# STM32WB55_CM0P register map
File version: 2.1
CPU: CM0 r0p1, little endian, MPU, no FPU, 4 interrupt priority bits
Registers are 32-bit, read-write, reset 0x0 unless marked. A register's access mark holds for its fields unless they carry their own. Offsets are from the block's base; [hi:lo] are bit positions; {n}, {i} and the like mark numbered series.

## GPIOH — General-purpose I/Os
Base 0x48001C00
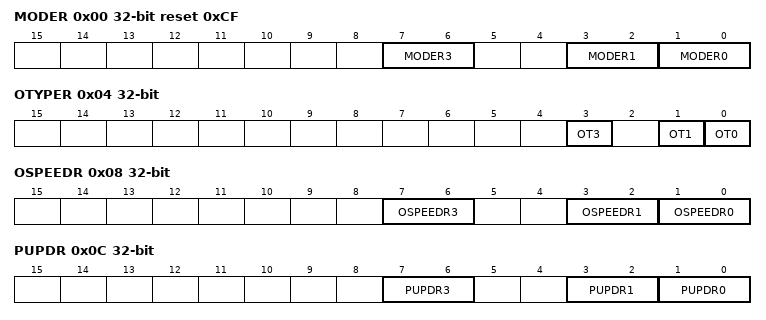
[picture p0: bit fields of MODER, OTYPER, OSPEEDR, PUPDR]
0x00 MODER reset 0xCF — GPIO port mode register
  [7:6] MODER3 — Port x configuration bits (y = 0..15)
  [3:2] MODER1 — Port x configuration bits (y = 0..15)
  [1:0] MODER0 — Port x configuration bits (y = 0..15)
0x04 OTYPER — GPIO port output type register
  [3] OT3 — Port x configuration bits (y = 0..15)
  [1] OT1 — Port x configuration bits (y = 0..15)
  [0] OT0 — Port x configuration bits (y = 0..15)
0x08 OSPEEDR — GPIO port output speed register
  [7:6] OSPEEDR3 — Port x configuration bits (y = 0..15)
  [3:2] OSPEEDR1 — Port x configuration bits (y = 0..15)
  [1:0] OSPEEDR0 — Port x configuration bits (y = 0..15)
0x0C PUPDR — GPIO port pull-up/pull-down register
  [7:6] PUPDR3 — Port x configuration bits (y = 0..15)
  [3:2] PUPDR1 — Port x configuration bits (y = 0..15)
  [1:0] PUPDR0 — Port x configuration bits (y = 0..15)
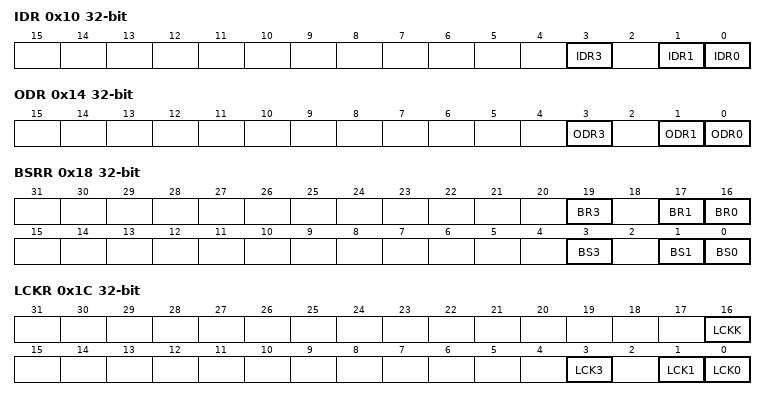
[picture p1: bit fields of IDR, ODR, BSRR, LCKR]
0x10 IDR ro — GPIO port input data register
  [3] IDR3 — Port input data (y = 0..15)
  [1] IDR1 — Port input data (y = 0..15)
  [0] IDR0 — Port input data (y = 0..15)
0x14 ODR — GPIO port output data register
  [3] ODR3 — Port output data (y = 0..15)
  [1] ODR1 — Port output data (y = 0..15)
  [0] ODR0 — Port output data (y = 0..15)
0x18 BSRR wo — GPIO port bit set/reset register
  [19] BR3 — Port x reset bit y (y = 0..15)
  [17] BR1 — Port x reset bit y (y = 0..15)
  [16] BR0 — Port x set bit y (y= 0..15)
  [3] BS3 — Port x set bit y (y= 0..15)
  [1] BS1 — Port x set bit y (y= 0..15)
  [0] BS0 — Port x set bit y (y= 0..15)
0x1C LCKR — GPIO port configuration lock register
  [16] LCKK — Port x lock bit y (y= 0..15)
  [3] LCK3 — Port x lock bit y (y= 0..15)
  [1] LCK1 — Port x lock bit y (y= 0..15)
  [0] LCK0 — Port x lock bit y (y= 0..15)
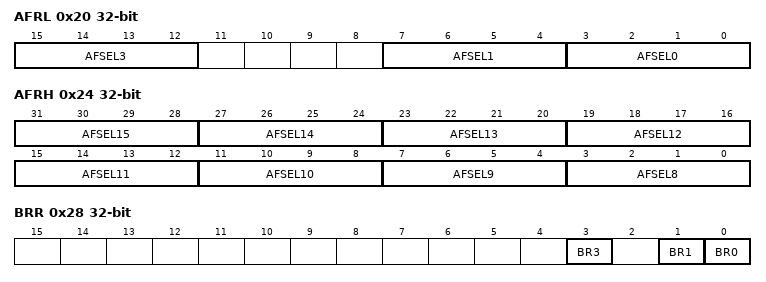
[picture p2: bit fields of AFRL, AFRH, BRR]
0x20 AFRL — GPIO alternate function low register
  [15:12] AFSEL3 — Alternate function selection for port x bit y (y = 0..7)
  [7:4] AFSEL1 — Alternate function selection for port x bit y (y = 0..7)
  [3:0] AFSEL0 — Alternate function selection for port x bit y (y = 0..7)
0x24 AFRH — GPIO alternate function high register
  [4n-29:4n-32] AFSEL{n} (n=8..15) — Alternate function selection for port x bit y (y = 8..15)
0x28 BRR wo — port bit reset register
  [3] BR3 — Port Reset bit
  [1] BR1 — Port Reset bit
  [0] BR0 — Port Reset bit

## TIM16 — General purpose timers
Base 0x40014400
Same registers: TIM17 0x40014800
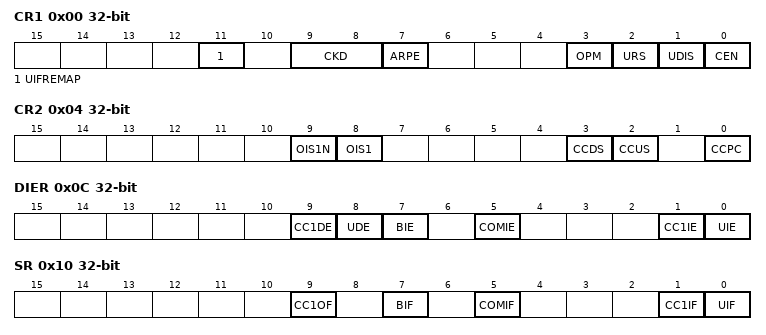
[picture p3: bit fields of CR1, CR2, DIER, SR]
0x00 CR1 — control register 1
  [11] UIFREMAP — UIF status bit remapping
  [9:8] CKD — Clock division
  [7] ARPE — Auto-reload preload enable
  [3] OPM — One-pulse mode
  [2] URS — Update request source
  [1] UDIS — Update disable
  [0] CEN — Counter enable
0x04 CR2 — control register 2
  [9] OIS1N — Output Idle state 1
  [8] OIS1 — Output Idle state 1
  [3] CCDS — Capture/compare DMA selection
  [2] CCUS — Capture/compare control update selection
  [0] CCPC — Capture/compare preloaded control
0x0C DIER — DMA/Interrupt enable register
  [9] CC1DE — Capture/Compare 1 DMA request enable
  [8] UDE — Update DMA request enable
  [7] BIE — Break interrupt enable
  [5] COMIE — COM interrupt enable
  [1] CC1IE — Capture/Compare 1 interrupt enable
  [0] UIE — Update interrupt enable
0x10 SR — status register
  [9] CC1OF — Capture/Compare 1 overcapture flag
  [7] BIF — Break interrupt flag
  [5] COMIF — COM interrupt flag
  [1] CC1IF — Capture/compare 1 interrupt flag
  [0] UIF — Update interrupt flag
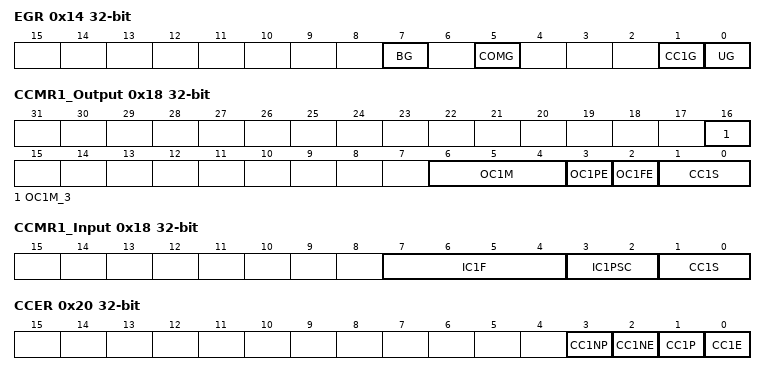
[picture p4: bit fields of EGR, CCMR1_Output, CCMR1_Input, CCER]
0x14 EGR wo — event generation register
  [7] BG — Break generation
  [5] COMG — Capture/Compare control update generation
  [1] CC1G — Capture/compare 1 generation
  [0] UG — Update generation
0x18 CCMR1_Output — capture/compare mode register (output mode)
  [16] OC1M_3 — Output Compare 1 mode
  [6:4] OC1M — Output Compare 1 mode
  [3] OC1PE — Output Compare 1 preload enable
  [2] OC1FE — Output Compare 1 fast enable
  [1:0] CC1S — Capture/Compare 1 selection
0x18 CCMR1_Input (alternate view of CCMR1_Output) — capture/compare mode register 1 (input mode)
  [7:4] IC1F — Input capture 1 filter
  [3:2] IC1PSC — Input capture 1 prescaler
  [1:0] CC1S — Capture/Compare 1 selection
0x20 CCER — capture/compare enable register
  [3] CC1NP — Capture/Compare 1 output Polarity
  [2] CC1NE — Capture/Compare 1 complementary output enable
  [1] CC1P — Capture/Compare 1 output Polarity
  [0] CC1E — Capture/Compare 1 output enable
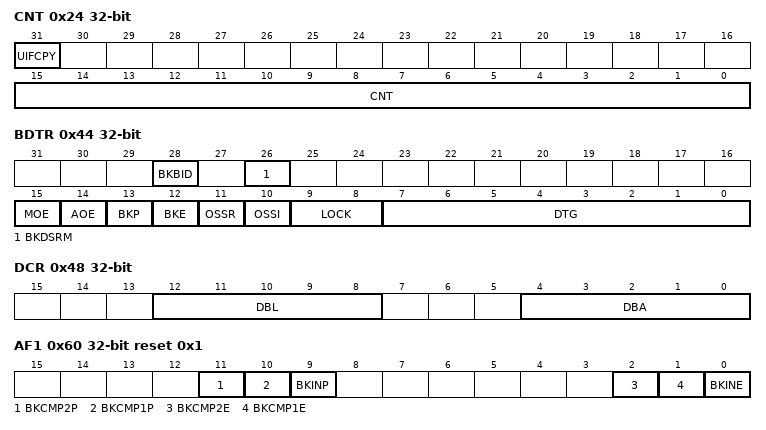
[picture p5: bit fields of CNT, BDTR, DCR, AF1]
0x24 CNT access per field — counter
  [31] UIFCPY ro — UIF Copy
  [15:0] CNT rw — counter value
0x28 PSC — prescaler
  [15:0] PSC — Prescaler value
0x2C ARR reset 0xFFFF — auto-reload register
  [15:0] ARR — Auto-reload value
0x30 RCR — repetition counter register
  [7:0] REP — Repetition counter value
0x34 CCR1 — capture/compare register 1
  [15:0] CCR1 — Capture/Compare 1 value
0x44 BDTR — break and dead-time register
  [28] BKBID — Break Bidirectional
  [26] BKDSRM — Break Disarm
  [15] MOE — Main output enable
  [14] AOE — Automatic output enable
  [13] BKP — Break polarity
  [12] BKE — Break enable
  [11] OSSR — Off-state selection for Run mode
  [10] OSSI — Off-state selection for Idle mode
  [9:8] LOCK — Lock configuration
  [7:0] DTG — Dead-time generator setup
0x48 DCR — DMA control register
  [12:8] DBL — DMA burst length
  [4:0] DBA — DMA base address
0x4C DMAR — DMA address for full transfer
  [15:0] DMAB — DMA register for burst accesses
0x50 OR1 — TIM option register 1
  [1:0] TI1_RMP — Input capture 1 remap
0x60 AF1 reset 0x1 — alternate function register 1
  [11] BKCMP2P — BRK COMP2 input polarit
  [10] BKCMP1P — BRK COMP1 input polarity
  [9] BKINP — BRK BKIN input polarity
  [2] BKCMP2E — BRK COMP2 enable
  [1] BKCMP1E — BRK COMP1 enable
  [0] BKINE — BRK BKIN input enable
0x68 TISEL — input selection register
  [3:0] TI1SEL — selects TI1[0] to TI1[15] input
